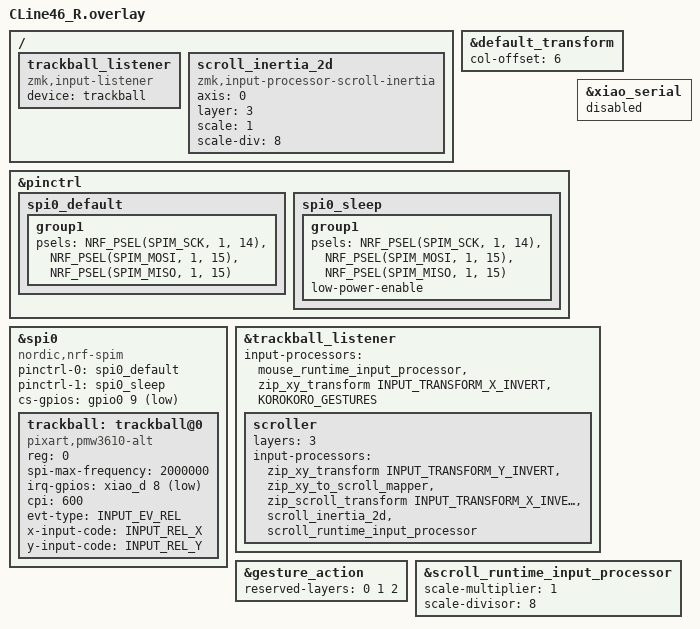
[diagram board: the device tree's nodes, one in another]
#include "CLine46.dtsi"
#include <zephyr/dt-bindings/input/input-event-codes.h>
#include <input/processors.dtsi>
#include <input/processors/runtime-input-processor.dtsi>
#include <behaviors/battery_history_request.dtsi>
#include <behaviors.dtsi>
#include <dt-bindings/zmk/keys.h>
#include <dt-bindings/zmk/mouse-gesture.h>
#include <behaviors/gesture_action.dtsi>
#include <presets/gesture_six_groups.dtsi>

&default_transform {
    col-offset = <6>;
};


/ {
    trackball_listener {
        status = "okay";
        compatible = "zmk,input-listener";
        device = <&trackball>;
    };
};

&pinctrl {
    spi0_default: spi0_default {
        group1 {
            psels = <NRF_PSEL(SPIM_SCK, 1, 14)>,
                <NRF_PSEL(SPIM_MOSI, 1, 15)>,
                <NRF_PSEL(SPIM_MISO, 1, 15)>;
        };
    };

    spi0_sleep: spi0_sleep {
        group1 {
            psels = <NRF_PSEL(SPIM_SCK, 1, 14)>,
                <NRF_PSEL(SPIM_MOSI, 1, 15)>,
                <NRF_PSEL(SPIM_MISO, 1, 15)>;
            low-power-enable;
        };
    };
};


&xiao_serial { status = "disabled"; };

&spi0 {
    status = "okay";
    compatible = "nordic,nrf-spim";
    pinctrl-0 = <&spi0_default>;
    pinctrl-1 = <&spi0_sleep>;
    pinctrl-names = "default", "sleep";
    cs-gpios = <&gpio0 9 GPIO_ACTIVE_LOW>;  //P0.09を指定(CS)

    trackball: trackball@0 {
        status = "okay";
        compatible = "pixart,pmw3610-alt";
        reg = <0>;
        spi-max-frequency = <2000000>;
        irq-gpios = <&xiao_d 8 (GPIO_ACTIVE_LOW | GPIO_PULL_UP)>;
        cpi = <600>;
        //swap-xy;
        evt-type = <INPUT_EV_REL>;
        x-input-code = <INPUT_REL_X>;
        y-input-code = <INPUT_REL_Y>;
    };
};

// Overrides for the input listener node
&trackball_listener {
    status = "okay";

    // ジェスチャーはレイヤー上書き(layers = <N>)ではなくベースチェーンに並べる。
    // どのレイヤーで動くかは各インスタンスの active-layers が決めるので、
    // レイヤーとグループの対応を再ビルドなしに変更できる。
    //
    // カーソル固定は suppress-movement が担当する。以前は STOP を返す実装が
    // 効かず zip_xy_scaler 0 1 で代用していたが、値を0に潰す方式に直したため
    // 不要になった。レイヤー上書きを使わないので X軸反転の二重指定も不要。
    input-processors =<&mouse_runtime_input_processor>,
        //<&zip_xy_transform INPUT_TRANSFORM_Y_INVERT>;         //Y軸反転
        //<&zip_xy_transform INPUT_TRANSFORM_XY_SWAP>,        //X軸とY軸の入れ替え
        <&zip_xy_transform INPUT_TRANSFORM_X_INVERT>,       //X軸反転
        //<&zip_temp_layer 2 1000>;                            //オートマウスレイヤーの選択;
        <KOROKORO_GESTURES>;

    scroller {
        layers = <3>;
        // 軸反転は本家と同じく静的プロセッサに任せる。ランタイム側へ移すと
        // 「標準状態=反転ON」になり、DYA Studio 上の表示と実際の向きの対応が
        // 分かりにくくなるため。PR #10 と同じ構成に揃えてある。
        input-processors =
            // <&zip_xy_transform INPUT_TRANSFORM_XY_SWAP>,        //X軸とY軸の入れ替え
            <&zip_xy_transform INPUT_TRANSFORM_Y_INVERT>,       //Y軸反転
            <&zip_xy_to_scroll_mapper>,                         //スクロールモードに変更
            <&zip_scroll_transform INPUT_TRANSFORM_X_INVERT>,   //スクロールのX軸反転
            <&scroll_inertia_2d>,                               //慣性スクロール(実験中)
            <&scroll_runtime_input_processor>;                  //スクロール量・軸スナップをDYA Studioから調整可能に
    };
};

// ジェスチャー本体(プロセッサ6個・スロット名・初期値)はモジュール同梱の
// プリセット <presets/gesture_six_groups.dtsi> が定義する。グループ1〜4は
// 既定のレイヤー7〜10のままなので、ここで上書きするものは無い。

/ {
    // 慣性スクロール。フリックしてボールを離すと、スクロールが減衰しながら続く。
    //
    // 惰性中の出力はプロセッサチェーンを通らず HID に直接注入されるため、
    //   - チェーン内の配置は「反転の後」でなければならない (でないと惰性だけ逆向きになる)
    //   - 後段の倍率をこのノード自身に教える必要がある (scale / scale-div)
    // scale-div = 8 は scroll_runtime_input_processor の初期値と同じ。DYA Studio で
    // 倍率を変えた場合、指で回している間は追従するが惰性はこの値のまま走る。
    //
    // axis = 0 は自由2D。従来のスクロール挙動を変えずに惰性だけ足す設定。
    scroll_inertia_2d: scroll_inertia_2d {
        compatible = "zmk,input-processor-scroll-inertia";
        #input-processor-cells = <0>;
        axis = <0>;
        layer = <3>;
        scale = <1>;
        scale-div = <8>;
    };
};

// ジェスチャー各スロットの初期値。
// スロット番号順に並べる (0=グループ1の上, 1=同下, 2=同左, 3=同右, 4=グループ2の上, ...)。
// 保存済みの割り当てがあればそちらが優先され、無ければここが使われる。
&gesture_action {
    // 設定画面がジェスチャーの割り当て先として出さないレイヤー。
    // ここに書くのは「方針として空けておきたい」ものだけ。
    //   0〜2 : 標準のキー配列とマウス操作。カーソルが止まると困る。
    reserved-layers = <0 1 2>;

    // listener の layer 上書きがあるレイヤー(現状はスクロールの3)は、
    // ジェスチャーを置いてもベースチェーンまで届かず無反応になる。
    // これはモジュール側が devicetree を走査して自動で追加するので、
    // ここに書く必要はない。scroller の layers を変更しても追従する。

};

// スクロール用のランタイム入力プロセッサ。
//
// 従来の <&zip_scroll_scaler 1 8> を置き換えたもの。scaler は再ビルドしないと
// 変更できなかったが、これに替えるとスクロール量を DYA Studio の
// 「トラックボール設定」から調整できるようになる。あわせて軸スナップ
// (移動を縦横どちらかに固定する機能。表計算ソフトなどで有用) も利用できる。
//
// 軸反転をここへ移すことも可能だが、そうすると「標準状態=反転ON」になり、
// DYA Studio 上の表示と実際の向きの対応が分かりにくくなる。本家 PR #10 と
// 同じく、反転は上の静的プロセッサに任せてある。
//
// 注意: このノードは runtime-input-processor.dtsi 内で /omit-if-no-ref/ 指定
// されているため、ここで参照して初めて firmware に組み込まれる。参照が無いと
// DYA Studio のプロセッサ一覧にも現れない。
//
// 下の初期値は従来の <&zip_scroll_scaler 1 8> と同じ 1/8 倍。
// 一度 DYA Studio で変更すると、そちらが保存されて以後優先される。
&scroll_runtime_input_processor {
    scale-multiplier = <1>;
    scale-divisor = <8>;
};
